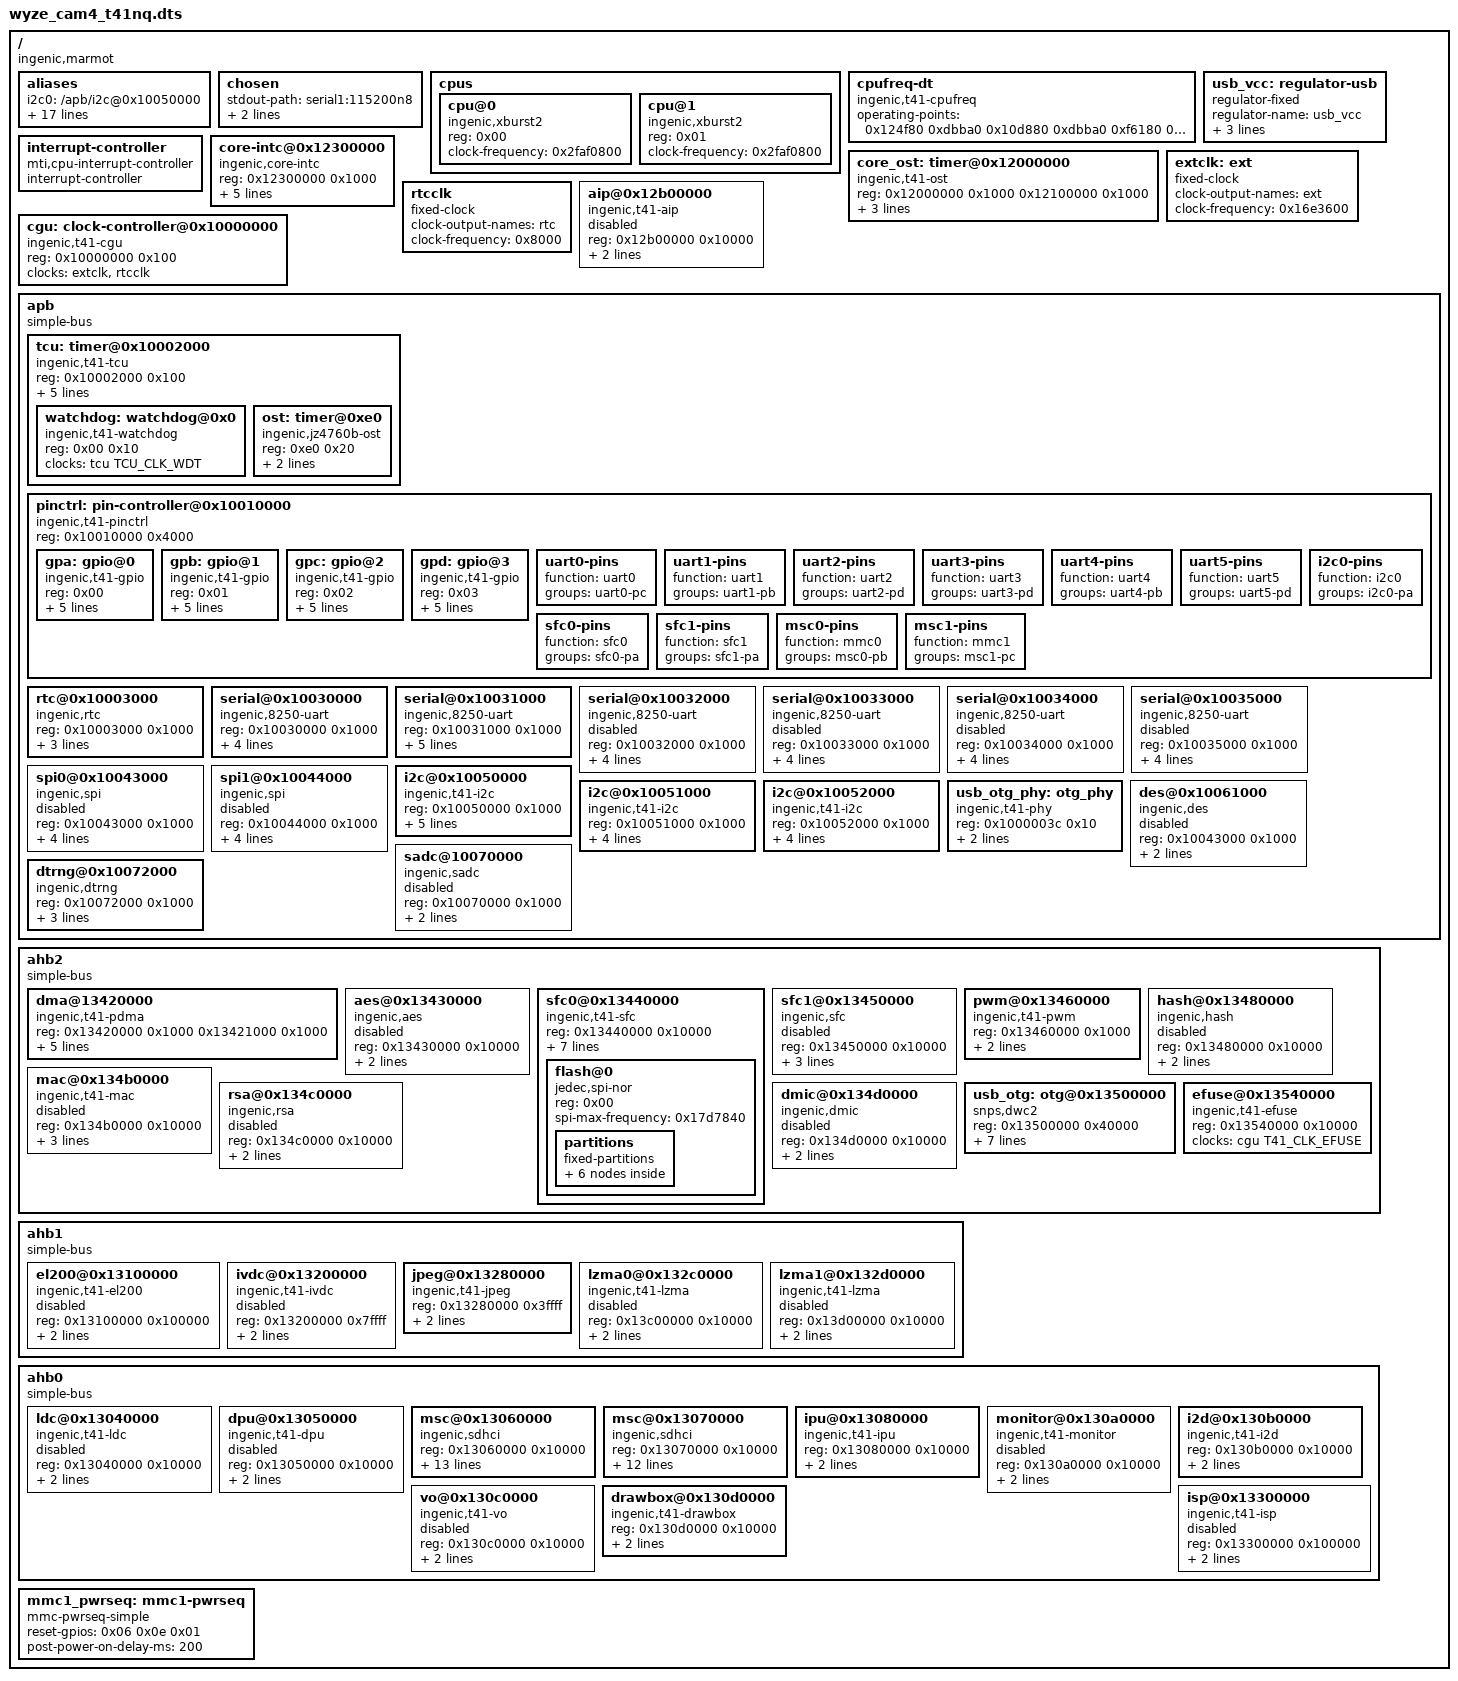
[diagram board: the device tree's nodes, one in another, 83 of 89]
/dts-v1/;

#include <dt-bindings/clock/ingenic,t41-cgu.h>
#include <dt-bindings/clock/ingenic,tcu.h>

/ {
	#address-cells = <0x01>;
	#size-cells = <0x01>;
	compatible = "ingenic,marmot", "ingenic,t41";

	aliases {
		i2c0 = "/apb/i2c@0x10050000";
		i2c1 = "/apb/i2c@0x10051000";
		i2c2 = "/apb/i2c@0x10052000";
		vo = "/ahb0/vo@0x130c0000";
		uart0 = "/apb/serial@0x10030000";
		uart1 = "/apb/serial@0x10031000";
		serial1 = "/apb/serial@0x10031000";
		uart2 = "/apb/serial@0x10032000";
		uart3 = "/apb/serial@0x10033000";
		uart4 = "/apb/serial@0x10034000";
		uart5 = "/apb/serial@0x10035000";
		msc0 = "/ahb0/msc@0x13060000";
		msc1 = "/ahb0/msc@0x13070000";
		mac0 = "/ahb2/mac@0x134b0000";
		spi0 = "/apb/spi0@0x10043000";
		spi1 = "/apb/spi1@0x10044000";
		sfc0 = "/ahb2/sfc0@0x13440000";
		sfc1 = "/ahb2/sfc1@0x13450000";
	};

	chosen {
		stdout-path = "serial1:115200n8";
		bootargs = "console=ttyS1,115200 root=/dev/mtdblock4 rootfstype=squashfs init=/init mem=100M@0x0 rmem=20M@0x6400000 nmem=8M@0x7800000 panic=5";
	};

	cpus {
		#address-cells = <0x01>;
		#size-cells = <0x00>;

		cpu@0 {
			device_type = "cpu";
			compatible = "ingenic,xburst2";
			reg = <0x00>;
			clock-frequency = <0x2faf0800>;
		};

		cpu@1 {
			device_type = "cpu";
			compatible = "ingenic,xburst2";
			reg = <0x01>;
			clock-frequency = <0x2faf0800>;
		};
	};

	cpufreq-dt {
		compatible = "ingenic,t41-cpufreq";
		status = "okay";
		operating-points = <0x124f80 0xdbba0 0x10d880 0xdbba0 0xf6180 0xdbba0 0xdea80 0xdbba0 0xd9878 0xdbba0 0xb71b0 0xdbba0 0x927c0 0xdbba0 0x7a120 0xdbba0 0x61a80 0xdbba0 0x5b8d8 0xdbba0 0x493e0 0xdbba0 0x30d40 0xdbba0>;
	};

	usb_vcc: regulator-usb {
		compatible = "regulator-fixed";
		regulator-name = "usb_vcc";
		regulator-min-microvolt = <3300000>;
		regulator-max-microvolt = <3300000>;
		regulator-always-on;
	};

	interrupt-controller {
		#address-cells = <0x00>;
		#interrupt-cells = <0x01>;
		interrupt-controller;
		compatible = "mti,cpu-interrupt-controller";
		linux,phandle = <0x01>;
		phandle = <0x01>;
	};

	core-intc@0x12300000 {
		compatible = "ingenic,core-intc";
		reg = <0x12300000 0x1000>;
		interrupt-controller;
		#interrupt-cells = <0x01>;
		cpu-intc-map = <0x00 0x00 0x01 0x100 0x02 0x200 0x03 0x300>;
		interrupt-parent = <0x01>;
		interrupts = <0x02>;
		interrupt-names = "intc";
		linux,phandle = <0x04>;
		phandle = <0x04>;
	};

	/*
	 * The T41's OS timers live outside the TCU: a global counter at
	 * 0x12000000 and a per-CPU compare timer at 0x12100000, 0x100
	 * apart, raising the core's IP4. The TCU channels on this part do
	 * not get a clock (EXT never reaches them).
	 */
	core_ost: timer@0x12000000 {
		compatible = "ingenic,t41-ost";
		reg = <0x12000000 0x1000 0x12100000 0x1000>;
		interrupt-parent = <0x01>;
		interrupt-names = "sys_ost";
		interrupts = <0x04>;

		clocks = <&extclk>;
		clock-names = "ost";

		#clock-cells = <0x01>;
	};

	/* The 8250_ingenic early console reads the frequency from /ext. */
	extclk: ext {
		compatible = "fixed-clock";
		clock-output-names = "ext";
		#clock-cells = <0x00>;
		clock-frequency = <0x16e3600>;
		linux,phandle = <0x02>;
		phandle = <0x02>;
	};

	rtcclk: rtcclk {
		compatible = "fixed-clock";
		clock-output-names = "rtc";
		#clock-cells = <0x00>;
		clock-frequency = <0x8000>;
		linux,phandle = <0x03>;
		phandle = <0x03>;
	};

	cgu: clock-controller@0x10000000 {
		compatible = "ingenic,t41-cgu";
		reg = <0x10000000 0x100>;
		clocks = <&extclk>, <&rtcclk>;
		clock-names = "ext", "rtc";
		#clock-cells = <0x01>;
	};

	aip@0x12b00000 {
		compatible = "ingenic,t41-aip";
		reg = <0x12b00000 0x10000>;
		interrupt-parent = <0x04>;
		interrupts = <0x28 0x27 0x26>;
		status = "disabled";
	};

	apb {
		compatible = "simple-bus";
		#address-cells = <0x01>;
		#size-cells = <0x01>;
		ranges;

		tcu: timer@0x10002000 {
			compatible = "ingenic,t41-tcu", "ingenic,jz4760-tcu",
				     "simple-mfd";
			reg = <0x10002000 0x100>;
			#address-cells = <0x01>;
			#size-cells = <0x01>;
			ranges = <0x00 0x10002000 0x100>;

			#clock-cells = <0x01>;

			clocks = <&cgu T41_CLK_RTCLK>, <&cgu T41_CLK_EXCLK>,
				 <&cgu T41_CLK_PCLK>, <&cgu T41_CLK_TCU>;
			clock-names = "rtc", "ext", "pclk", "tcu";

			interrupt-controller;
			#interrupt-cells = <0x01>;

			interrupt-parent = <0x04>;
			interrupts = <0x1b 0x1a 0x19>;

			watchdog: watchdog@0x0 {
				compatible = "ingenic,t41-watchdog", "ingenic,jz4780-watchdog";
				reg = <0x00 0x10>;

				clocks = <&tcu TCU_CLK_WDT>;
				clock-names = "wdt";
			};

			ost: timer@0xe0 {
				compatible = "ingenic,jz4760b-ost";
				reg = <0xe0 0x20>;

				clocks = <&tcu TCU_CLK_OST>;
				clock-names = "ost";

				interrupts = <0x0f>;
			};
		};

		pinctrl: pin-controller@0x10010000 {
			compatible = "ingenic,t41-pinctrl";
			reg = <0x10010000 0x4000>;

			#address-cells = <0x01>;
			#size-cells = <0x00>;

			gpa: gpio@0 {
				compatible = "ingenic,t41-gpio";
				reg = <0x00>;

				gpio-controller;
				gpio-ranges = <&pinctrl 0 0 32>;
				#gpio-cells = <0x02>;

				interrupt-controller;
				#interrupt-cells = <0x02>;

				interrupt-parent = <0x04>;
				interrupts = <0x11>;

				linux,phandle = <0x08>;
				phandle = <0x08>;
			};

			gpb: gpio@1 {
				compatible = "ingenic,t41-gpio";
				reg = <0x01>;

				gpio-controller;
				gpio-ranges = <&pinctrl 0 32 32>;
				#gpio-cells = <0x02>;

				interrupt-controller;
				#interrupt-cells = <0x02>;

				interrupt-parent = <0x04>;
				interrupts = <0x10>;

				linux,phandle = <0x05>;
				phandle = <0x05>;
			};

			gpc: gpio@2 {
				compatible = "ingenic,t41-gpio";
				reg = <0x02>;

				gpio-controller;
				gpio-ranges = <&pinctrl 0 64 32>;
				#gpio-cells = <0x02>;

				interrupt-controller;
				#interrupt-cells = <0x02>;

				interrupt-parent = <0x04>;
				interrupts = <0x0f>;

				linux,phandle = <0x06>;
				phandle = <0x06>;
			};

			gpd: gpio@3 {
				compatible = "ingenic,t41-gpio";
				reg = <0x03>;

				gpio-controller;
				gpio-ranges = <&pinctrl 0 96 32>;
				#gpio-cells = <0x02>;

				interrupt-controller;
				#interrupt-cells = <0x02>;

				interrupt-parent = <0x04>;
				interrupts = <0x0e>;

				linux,phandle = <0x07>;
				phandle = <0x07>;
			};

			uart0-pins {
				function = "uart0";
				groups = "uart0-pc";
				phandle = <0x30>;
			};

			uart1-pins {
				function = "uart1";
				groups = "uart1-pb";
				phandle = <0x31>;
			};

			uart2-pins {
				function = "uart2";
				groups = "uart2-pd";
				phandle = <0x32>;
			};

			uart3-pins {
				function = "uart3";
				groups = "uart3-pd";
				phandle = <0x33>;
			};

			uart4-pins {
				function = "uart4";
				groups = "uart4-pb";
				phandle = <0x34>;
			};

			uart5-pins {
				function = "uart5";
				groups = "uart5-pd";
				phandle = <0x35>;
			};

			i2c0-pins {
				function = "i2c0";
				groups = "i2c0-pa";
				phandle = <0x36>;
			};

			sfc0-pins {
				function = "sfc0";
				groups = "sfc0-pa";
				phandle = <0x37>;
			};

			sfc1-pins {
				function = "sfc1";
				groups = "sfc1-pa";
				phandle = <0x38>;
			};

			msc0-pins {
				function = "mmc0";
				groups = "msc0-pb";
				phandle = <0x39>;
			};

			msc1-pins {
				function = "mmc1";
				groups = "msc1-pc";
				phandle = <0x3a>;
			};
			};


			rtc@0x10003000 {
				compatible = "ingenic,rtc", "ingenic,jz4780-rtc";
				reg = <0x10003000 0x1000>;
				interrupt-parent = <0x04>;
				interrupts = <0x03>;
				clocks = <&rtcclk>;
				clock-names = "rtc";
				status = "okay";
			};

			serial@0x10030000 {
				compatible = "ingenic,8250-uart";
				reg = <0x10030000 0x1000>;
				reg-shift = <0x02>;
				interrupt-parent = <0x04>;
				interrupts = <0x33>;
				pinctrl-names = "default";
				pinctrl-0 = <0x30>;
				status = "okay";
			};

			serial@0x10031000 {
				compatible = "ingenic,8250-uart";
				reg = <0x10031000 0x1000>;
				reg-shift = <0x02>;
				interrupt-parent = <0x04>;
				interrupts = <0x32>;
				/* baud first, then the CGU module gate */
				clocks = <&extclk>, <&cgu T41_CLK_UART1>;
				clock-names = "baud", "module";
				pinctrl-names = "default";
				pinctrl-0 = <0x31>;
				status = "okay";
			};

			serial@0x10032000 {
				compatible = "ingenic,8250-uart";
				reg = <0x10032000 0x1000>;
				reg-shift = <0x02>;
				interrupt-parent = <0x04>;
				interrupts = <0x31>;
				pinctrl-names = "default";
				pinctrl-0 = <0x32>;
				status = "disabled";
			};

			serial@0x10033000 {
				compatible = "ingenic,8250-uart";
				reg = <0x10033000 0x1000>;
				reg-shift = <0x02>;
				interrupt-parent = <0x04>;
				interrupts = <0x30>;
				pinctrl-names = "default";
				pinctrl-0 = <0x33>;
				status = "disabled";
			};

			serial@0x10034000 {
				compatible = "ingenic,8250-uart";
				reg = <0x10034000 0x1000>;
				reg-shift = <0x02>;
				interrupt-parent = <0x04>;
				interrupts = <0x39>;
				pinctrl-names = "default";
				pinctrl-0 = <0x34>;
				status = "disabled";
			};

			serial@0x10035000 {
				compatible = "ingenic,8250-uart";
				reg = <0x10035000 0x1000>;
				reg-shift = <0x02>;
				interrupt-parent = <0x04>;
				interrupts = <0x38>;
				pinctrl-names = "default";
				pinctrl-0 = <0x35>;
				status = "disabled";
			};

			spi0@0x10043000 {
				compatible = "ingenic,spi";
				reg = <0x10043000 0x1000>;
				interrupt-parent = <0x04>;
				interrupts = <0x09>;
				dmas = <0x0f 0x16 0xffffffff 0x0f 0x17 0xffffffff>;
				dma-names = "tx", "rx";
				#address-cells = <0x01>;
				#size-cells = <0x00>;
				status = "disabled";
			};

			spi1@0x10044000 {
				compatible = "ingenic,spi";
				reg = <0x10044000 0x1000>;
				interrupt-parent = <0x04>;
				interrupts = <0x08>;
				dmas = <0x0f 0x18 0xffffffff 0x0f 0x19 0xffffffff>;
				dma-names = "tx", "rx";
				#address-cells = <0x01>;
				#size-cells = <0x00>;
				status = "disabled";
			};

			i2c@0x10050000 {
				compatible = "ingenic,t41-i2c", "ingenic,t31-i2c";
				reg = <0x10050000 0x1000>;
				interrupt-parent = <0x04>;
				interrupts = <0x3c>;
				clocks = <&cgu T41_CLK_I2C0>;
				clock-names = "i2c";
				clock-frequency = <0x61a80>;
				#address-cells = <0x01>;
				#size-cells = <0x00>;
				status = "okay";
				pinctrl-0 = <0x36>;
				pinctrl-names = "default";
			};

			i2c@0x10051000 {
				compatible = "ingenic,t41-i2c", "ingenic,t31-i2c";
				reg = <0x10051000 0x1000>;
				interrupt-parent = <0x04>;
				interrupts = <0x3b>;
				clocks = <&cgu T41_CLK_I2C1>;
				clock-names = "i2c";
				clock-frequency = <0x61a80>;
				#address-cells = <0x01>;
				#size-cells = <0x00>;
				status = "okay";
			};

			i2c@0x10052000 {
				compatible = "ingenic,t41-i2c", "ingenic,t31-i2c";
				reg = <0x10052000 0x1000>;
				interrupt-parent = <0x04>;
				interrupts = <0x3a>;
				clocks = <&cgu T41_CLK_I2C2>;
				clock-names = "i2c";
				clock-frequency = <0x61a80>;
				#address-cells = <0x01>;
				#size-cells = <0x00>;
				status = "okay";
			};

			usb_otg_phy: otg_phy {
				compatible = "ingenic,t41-phy";
				reg = <0x1000003c 0x10>;
				clocks = <&cgu T41_CLK_OTG>;
				vcc-supply = <&usb_vcc>;
				#phy-cells = <0x00>;
				status = "okay";
				linux,phandle = <0x13>;
				phandle = <0x13>;
			};

			des@0x10061000 {
				compatible = "ingenic,des";
				reg = <0x10043000 0x1000>;
				dmas = <0x0f 0x2e 0xffffffff 0x0f 0x2f 0xffffffff>;
				dma-names = "tx", "rx";
				#address-cells = <0x01>;
				#size-cells = <0x00>;
				status = "disabled";
			};

			sadc@10070000 {
				compatible = "ingenic,sadc";
				reg = <0x10070000 0x1000>;
				interrupt-parent = <0x04>;
				interrupts = <0x12>;
				status = "disabled";
			};

			dtrng@0x10072000 {
				compatible = "ingenic,dtrng", "ingenic,t31-dtrng";
				reg = <0x10072000 0x1000>;
				interrupt-parent = <0x04>;
				interrupts = <0x22>;
				clocks = <&cgu T41_CLK_DTRNG>;
				clock-names = "dtrng";
				status = "okay";
			};
		};

		ahb2 {
			compatible = "simple-bus";
			#address-cells = <0x01>;
			#size-cells = <0x01>;
			ranges;

			dma@13420000 {
				compatible = "ingenic,t41-pdma", "ingenic,t41-dma";
				reg = <0x13420000 0x1000 0x13421000 0x1000>;
				interrupt-parent = <0x04>;
				interrupt-names = "pdma", "pdmam";
				interrupts = <0x0a 0x3d>;
				clocks = <&cgu T41_CLK_PDMA>;
				clock-names = "pdma";
				dma-channels = <0x20>;
				#dma-cells = <0x02>;
				ingenic,reserved-channels = <0x03>;
				status = "okay";
				linux,phandle = <0x0f>;
				phandle = <0x0f>;
			};

			aes@0x13430000 {
				compatible = "ingenic,aes";
				reg = <0x13430000 0x10000>;
				interrupt-parent = <0x04>;
				interrupts = <0x17>;
				status = "disabled";
			};

			sfc0@0x13440000 {
				compatible = "ingenic,t41-sfc", "ingenic,x2000-sfc";
				reg = <0x13440000 0x10000>;
				clocks = <&cgu T41_CLK_SFC0>;
				clock-names = "sfc";
				#address-cells = <0x01>;
				#size-cells = <0x00>;
				interrupt-parent = <0x04>;
				interrupts = <0x07>;
				status = "okay";
				ingenic,sfc-max-frequency = <0x5f5e100>;
				ingenic,use_board_info = [00];
				ingenic,spiflash_param_offset = <0x00>;
				ingenic,spiflash_type = <0x00>;

				flash@0 {
					compatible = "jedec,spi-nor";
					reg = <0x00>;
					spi-max-frequency = <0x17d7840>;

					partitions {
						compatible = "fixed-partitions";
						#address-cells = <0x01>;
						#size-cells = <0x01>;

						partition@0 {
							label = "boot";
							reg = <0x0 0x40000>;
							read-only;
						};

						partition@40000 {
							label = "env";
							reg = <0x40000 0x10000>;
						};

						partition@50000 {
							label = "backup";
							reg = <0x50000 0x10000>;
						};

						partition@60000 {
							label = "kernel";
							reg = <0x60000 0x300000>;
						};

						partition@360000 {
							label = "rootfs";
							reg = <0x360000 0x600000>;
						};

						partition@960000 {
							label = "data";
							reg = <0x960000 0x6a0000>;
						};
					};
				};
			};

			sfc1@0x13450000 {
				compatible = "ingenic,sfc";
				reg = <0x13450000 0x10000>;
				interrupt-parent = <0x04>;
				interrupts = <0x13>;
				pinctrl-names = "default";
				pinctrl-0 = <0x38>;
				status = "disabled";
			};

			pwm@0x13460000 {
				compatible = "ingenic,t41-pwm";
				reg = <0x13460000 0x1000>;
				interrupt-parent = <0x04>;
				interrupts = <0x3f>;
				#address-cells = <0x01>;
				#size-cells = <0x00>;
				status = "okay";
			};

			hash@0x13480000 {
				compatible = "ingenic,hash";
				reg = <0x13480000 0x10000>;
				interrupt-parent = <0x04>;
				interrupts = <0x16>;
				status = "disabled";
			};

			mac@0x134b0000 {
				compatible = "ingenic,t41-mac";
				reg = <0x134b0000 0x10000>;
				interrupt-parent = <0x04>;
				interrupts = <0x37>;
				status = "disabled";
				ingenic,rst-ms = <0x0a>;
			};

			rsa@0x134c0000 {
				compatible = "ingenic,rsa";
				reg = <0x134c0000 0x10000>;
				interrupt-parent = <0x04>;
				interrupts = <0x18>;
				status = "disabled";
			};

			dmic@0x134d0000 {
				compatible = "ingenic,dmic";
				reg = <0x134d0000 0x10000>;
				interrupt-parent = <0x04>;
				interrupts = <0x21>;
				status = "disabled";
			};

			usb_otg: otg@0x13500000 {
				compatible = "snps,dwc2";
				reg = <0x13500000 0x40000>;
				interrupt-parent = <0x04>;
				interrupts = <0x15>;
				phys = <&usb_otg_phy>;
				phy-names = "usb2-phy";
				dr_mode = "peripheral";
				maximum-speed = "full-speed";
				g-rx-fifo-size = <1024>;
				g-np-tx-fifo-size = <256>;
				status = "okay";
			};

			efuse@0x13540000 {
				compatible = "ingenic,t41-efuse";
				reg = <0x13540000 0x10000>;
				clocks = <&cgu T41_CLK_EFUSE>;
				status = "okay";
			};
		};

		ahb1 {
			compatible = "simple-bus";
			#address-cells = <0x01>;
			#size-cells = <0x01>;
			ranges;

			el200@0x13100000 {
				compatible = "ingenic,t41-el200";
				reg = <0x13100000 0x100000>;
				interrupt-parent = <0x04>;
				interrupts = <0x3e>;
				status = "disabled";
			};

			ivdc@0x13200000 {
				compatible = "ingenic,t41-ivdc";
				reg = <0x13200000 0x7ffff>;
				interrupt-parent = <0x04>;
				interrupts = <0x00>;
				status = "disabled";
			};

			jpeg@0x13280000 {
				compatible = "ingenic,t41-jpeg";
				reg = <0x13280000 0x3ffff>;
				interrupt-parent = <0x04>;
				interrupts = <0x00>;
				status = "okay";
			};

			lzma0@0x132c0000 {
				compatible = "ingenic,t41-lzma";
				reg = <0x13c00000 0x10000>;
				interrupt-parent = <0x04>;
				interrupts = <0x04>;
				status = "disabled";
			};

			lzma1@0x132d0000 {
				compatible = "ingenic,t41-lzma";
				reg = <0x13d00000 0x10000>;
				interrupt-parent = <0x04>;
				interrupts = <0x04>;
				status = "disabled";
			};
		};

		ahb0 {
			compatible = "simple-bus";
			#address-cells = <0x01>;
			#size-cells = <0x01>;
			ranges;

			ldc@0x13040000 {
				compatible = "ingenic,t41-ldc";
				reg = <0x13040000 0x10000>;
				interrupt-parent = <0x04>;
				interrupts = <0x23>;
				status = "disable";
			};

			dpu@0x13050000 {
				compatible = "ingenic,t41-dpu";
				reg = <0x13050000 0x10000>;
				interrupt-parent = <0x04>;
				interrupts = <0x14>;
				status = "disabled";
			};

			msc@0x13060000 {
				compatible = "ingenic,sdhci";
				reg = <0x13060000 0x10000>;
				clocks = <&cgu T41_CLK_MSC0>;
				status = "okay";
				interrupt-parent = <0x04>;
				interrupts = <0x25>;
				pinctrl-names = "default";
				pinctrl-0 = <0x39>;
				cap-mmc-highspeed;
				max-frequency = <0x17d7840>;
				bus-width = <0x04>;
				voltage-ranges = <0x708 0xce4>;
				cd-inverted;
				cd-gpios = <0x05 0x1a 0x01>;
				ingenic,wp-gpios = <0x00>;
				ingenic,cd-gpios = <0x05 0x1a 0x01>;
				ingenic,rst-gpios = <0x00>;
			};

			msc@0x13070000 {
				compatible = "ingenic,sdhci";
				reg = <0x13070000 0x10000>;
				clocks = <&cgu T41_CLK_MSC1>;
				status = "okay";
				interrupt-parent = <0x04>;
				interrupts = <0x24>;
				pinctrl-names = "default";
				pinctrl-0 = <0x3a>;
				cap-mmc-highspeed;
				max-frequency = <0x17d7840>;
				bus-width = <0x04>;
				voltage-ranges = <0x708 0xce4>;
				non-removable;
				ingenic,wp-gpios = <0x00>;
				ingenic,rst-gpios = <0x06 0x0e 0x01>;
				mmc-pwrseq = <&mmc1_pwrseq>;
			};

			ipu@0x13080000 {
				compatible = "ingenic,t41-ipu";
				reg = <0x13080000 0x10000>;
				interrupt-parent = <0x04>;
				interrupts = <0x06>;
				status = "okay";
			};

			monitor@0x130a0000 {
				compatible = "ingenic,t41-monitor";
				reg = <0x130a0000 0x10000>;
				interrupt-parent = <0x04>;
				interrupts = <0x35>;
				status = "disabled";
			};

			i2d@0x130b0000 {
				compatible = "ingenic,t41-i2d";
				reg = <0x130b0000 0x10000>;
				interrupt-parent = <0x04>;
				interrupts = <0x2d>;
				status = "okay";
			};

			vo@0x130c0000 {
				compatible = "ingenic,t41-vo";
				reg = <0x130c0000 0x10000>;
				interrupt-parent = <0x04>;
				interrupts = <0x2b>;
				status = "disabled";
			};

			drawbox@0x130d0000 {
				compatible = "ingenic,t41-drawbox";
				reg = <0x130d0000 0x10000>;
				interrupt-parent = <0x04>;
				interrupts = <0x2a>;
				status = "okay";
			};

			isp@0x13300000 {
				compatible = "ingenic,t41-isp";
				reg = <0x13300000 0x100000>;
				interrupt-parent = <0x04>;
				interrupts = <0x1f>;
				status = "disabled";
			};
		};


		mmc1_pwrseq: mmc1-pwrseq {
			compatible = "mmc-pwrseq-simple";
			reset-gpios = <0x06 0x0e 0x01>;
			post-power-on-delay-ms = <200>;
		};

	};
